# PIC32CX2051BZ66048 device description
Architecture: CORTEX-M4; Family: PIC32CX; Series: PIC32CXBZ66
Registers are 32-bit, read-write, reset 0x0 unless marked. A register's access mark holds for its fields unless they carry their own. Offsets are from the block's base; [hi:lo] are bit positions; <NAME> marks a mode.

## DAC_CTRL — Descriptive Title of Macro
Instances: DAC_CTRL 0x44002E00
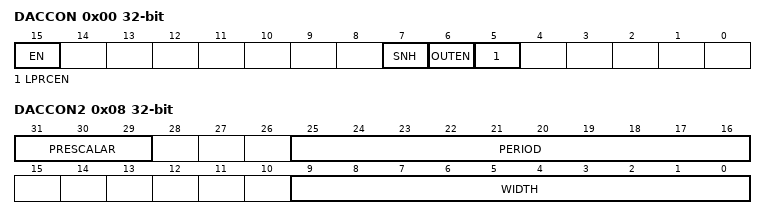
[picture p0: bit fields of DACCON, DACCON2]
0x00 DACCON — CONTROL Register
  [15] EN — Enable
    0=The peripheral is disabled; 1=The peripheral is enabled
  [7] SNH — Sample and hold circuitry
    0=DAC operation in normal mode; 1=DAC operation in low power mode
  [6] OUTEN — Will enable the output buffer
    0=Output buffer disabled; 1=Output buffer enabled
  [5] LPRCEN — LPRC clock enabled for SnH mode
    0=LPRC clock not enabled; 1=LPRC clock enabled
0x04 DACCODE
  [6:0] DATA — DAC data
0x08 DACCON2 — DAC Config register1
  [31:29] PRESCALAR — Prescaling factor for SnH clock
  [25:16] PERIOD — SnH clock period
  [9:0] WIDTH — SnH clock width

## DMAC_DESCRIPTOR — Direct Memory Access Controller
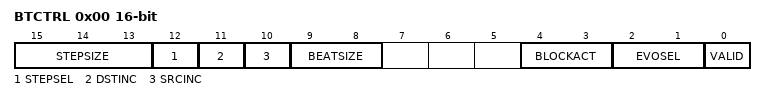
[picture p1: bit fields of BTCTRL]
0x00 BTCTRL 16-bit — Block Transfer Control
  [15:13] STEPSIZE — Address Increment Step Size
    0=Next ADDR = ADDR + (1<<BEATSIZE) * 1; 1=X2 (Next ADDR = ADDR + (1<<BEATSIZE) * 2); 2=X4 (Next ADDR = ADDR + (1<<BEATSIZE) * 4); 3=X8 (Next ADDR = ADDR + (1<<BEATSIZE) * 8); 4=X16 (Next ADDR = ADDR + (1<<BEATSIZE) * 16); 5=X32 (Next ADDR = ADDR + (1<<BEATSIZE) * 32); 6=X64 (Next ADDR = ADDR + (1<<BEATSIZE) * 64); 7=X128 (Next ADDR = ADDR + (1<<BEATSIZE) * 128)
  [12] STEPSEL — Step Selection
    0=DST (Step size settings apply to the destination address); 1=SRC (Step size settings apply to the source address)
  [11] DSTINC — Destination Address Increment Enable
  [10] SRCINC — Source Address Increment Enable
  [9:8] BEATSIZE
    0=BYTE (8-bit bus transfer); 1=HWORD (16-bit bus transfer); 2=WORD (32-bit bus transfer)
  [4:3] BLOCKACT — Block Action
    0=NOACT (Channel will be disabled if it is the last block transfer in the transaction); 1=INT (Channel will be disabled if it is the last block transfer in the transaction and block interrupt); 2=SUSPEND (Channel suspend operation is completed); 3=BOTH (Both channel suspend operation and block interrupt)
  [2:1] EVOSEL — Block Event Output Selection
    0=DISABLE (Event generation disabled); 1=BLOCK (Block event strobe); 3=BURST (Burst event strobe)
  [0] VALID — Descriptor Valid
0x02 BTCNT 16-bit — Block Transfer Count
0x04 SRCADDR — Block Transfer Source Address
  [31:0] SRCADDR — Transfer Source Address
0x08 DSTADDR reset not defined — Block Transfer Destination Address
  [31:0] CHKINIT <CRC> — CRC Checksum Initial Value
  [31:0] DSTADDR <DEFAULT> — Transfer Destination Address
0x0C DESCADDR reset not defined — Next Descriptor Address

## DMT — Dead Man Timer
Instances: DMT 0x44000E00
0x00 DMTCON
  [15] ON
0x04 DMTCONCLR — Bit clear register
0x08 DMTCONSET — Bit set register
0x0C DMTCONINV — Bit invert register
0x10 DMTPRECLR
  [15:8] STEP1
0x14 DMTPRECLRCLR — Bit clear register
0x18 DMTPRECLRSET — Bit set register
0x1C DMTPRECLRINV — Bit invert register
0x20 DMTCLR
  [7:0] STEP2
0x24 DMTCLRCLR — Bit clear register
0x28 DMTCLRSET — Bit set register
0x2C DMTCLRINV — Bit invert register
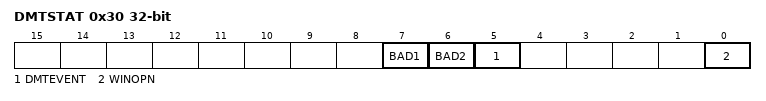
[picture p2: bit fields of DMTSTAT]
0x30 DMTSTAT
  [7] BAD1, [6] BAD2, [5] DMTEVENT, [0] WINOPN
0x34 DMTSTATCLR — Bit clear register
0x38 DMTSTATSET — Bit set register
0x3C DMTSTATINV — Bit invert register
0x40 DMTCNT ro
  [31:0] COUNTER
0x44 DMTCNTCLR — Bit clear register
0x48 DMTCNTSET — Bit set register
0x4C DMTCNTINV — Bit invert register
0x50 DMTHOLDREG ro
  [15:0] UPRCNT
0x54 DMTHOLDREGCLR — Bit clear register
0x58 DMTHOLDREGSET — Bit set register
0x5C DMTHOLDREGINV — Bit invert register
0x60 DMTPSCNT ro
  [31:0] PSCNT
0x64 DMTPSCNTCLR — Bit clear register
0x68 DMTPSCNTSET — Bit set register
0x6C DMTPSCNTINV — Bit invert register
0x70 DMTPSINTV ro
  [31:0] PSINTV
0x74 DMTPSINTVCLR — Bit clear register
0x78 DMTPSINTVSET — Bit set register
0x7C DMTPSINTVINV — Bit invert register
